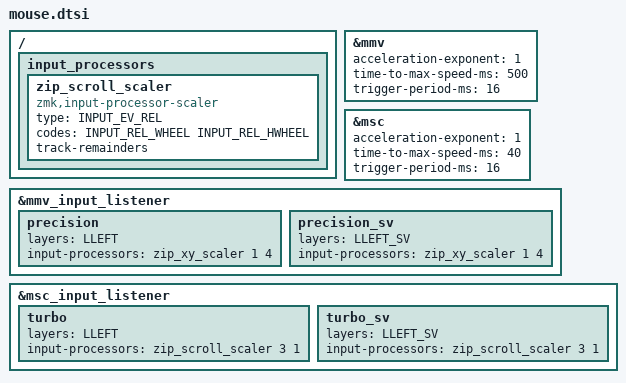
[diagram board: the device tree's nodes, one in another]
#include <zephyr/dt-bindings/input/input-event-codes.h>

// Inspired by caksoylar's config

#define ZMK_POINTING_DEFAULT_MOVE_VAL 1500  // 600
#define ZMK_POINTING_DEFAULT_SCRL_VAL 20    // 10

#include <dt-bindings/zmk/pointing.h>
#include <input/processors.dtsi>

&mmv {
    acceleration-exponent = <1>;      // 1
    time-to-max-speed-ms = <500>;     // 300
    trigger-period-ms = <16>;
};

&msc {
    acceleration-exponent = <1>;      // 0
    time-to-max-speed-ms = <40>;      // 300
    trigger-period-ms = <16>;
};

&mmv_input_listener {
    precision {
        layers = <LLEFT>;
        input-processors = <&zip_xy_scaler 1 4>;
    };
    precision_sv {
        layers = <LLEFT_SV>;
        input-processors = <&zip_xy_scaler 1 4>;
    };
};

/ {
    input_processors {
        zip_scroll_scaler: zip_scroll_scaler {
            compatible = "zmk,input-processor-scaler";
            #input-processor-cells = <2>;
            type = <INPUT_EV_REL>;
            codes = <INPUT_REL_WHEEL INPUT_REL_HWHEEL>;
            track-remainders;
        };
    };
};

&msc_input_listener {
    turbo {
        layers = <LLEFT>;
        input-processors = <&zip_scroll_scaler 3 1>;
    };
    turbo_sv {
        layers = <LLEFT_SV>;
        input-processors = <&zip_scroll_scaler 3 1>;
    };

};

// Mouse wheel
#define U_WH_U &msc SCRL_UP
#define U_WH_D &msc SCRL_DOWN
#define U_WH_L &msc SCRL_LEFT
#define U_WH_R &msc SCRL_RIGHT

// Mouse Movement
#define U_MS_U &mmv MOVE_UP
#define U_MS_D &mmv MOVE_DOWN
#define U_MS_L &mmv MOVE_LEFT
#define U_MS_R &mmv MOVE_RIGHT

// Mouse Click
#define M_LCLK &mkp LCLK
#define M_MCLK &mkp MCLK
#define M_RCLK &mkp RCLK
#define M_MB4 &mkp MB4
#define M_MB5 &mkp MB5
